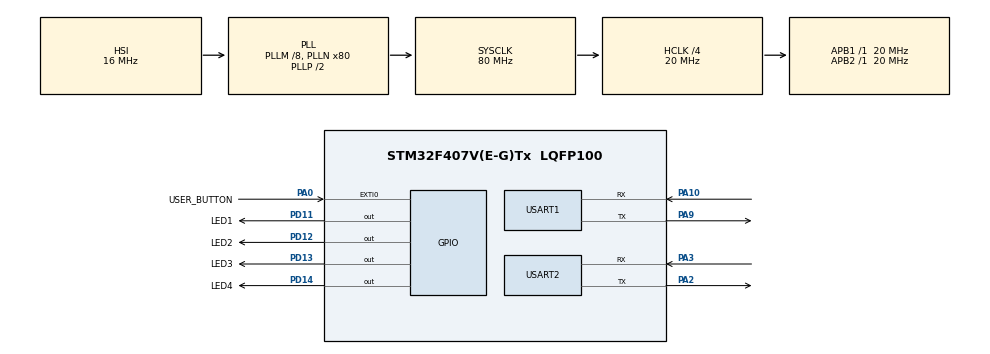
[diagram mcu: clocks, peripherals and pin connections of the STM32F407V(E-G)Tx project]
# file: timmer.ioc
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Mcu.Family=STM32F4
Mcu.Name=STM32F407V(E-G)Tx
Mcu.Package=LQFP100
NVIC.PriorityGroup=NVIC_PRIORITYGROUP_4
NVIC.TIM1_UP_TIM10_IRQn=true\:0\:0\:false\:false\:true\:true\:true\:true
PA0-WKUP.GPIO_Label=USER_BUTTON
PA0-WKUP.Signal=GPXTI0
PA10.Mode=Asynchronous
PA10.Signal=USART1_RX
PA2.Mode=Asynchronous
PA2.Signal=USART2_TX
PA3.Mode=Asynchronous
PA3.Signal=USART2_RX
PA9.Mode=Asynchronous
PA9.Signal=USART1_TX
PD11.GPIO_Label=LED1
PD11.Signal=GPIO_Output
PD12.GPIO_Label=LED2
PD12.Signal=GPIO_Output
PD13.GPIO_Label=LED3
PD13.Signal=GPIO_Output
PD14.GPIO_Label=LED4
PD14.Signal=GPIO_Output
ProjectManager.HeapSize=0x200
ProjectManager.StackSize=0x400
ProjectManager.TargetToolchain=Makefile
RCC.48MHZClocksFreq_Value=40000000
RCC.AHBCLKDivider=RCC_SYSCLK_DIV4
RCC.AHBFreq_Value=20000000
RCC.APB1Freq_Value=20000000
RCC.APB1TimFreq_Value=20000000
RCC.APB2Freq_Value=20000000
RCC.APB2TimFreq_Value=20000000
RCC.CortexFreq_Value=20000000
RCC.HCLKFreq_Value=20000000
RCC.HSE_VALUE=25000000
RCC.HSI_VALUE=16000000
RCC.LSE_VALUE=32768
RCC.PLLM=8
RCC.PLLN=80
RCC.SYSCLKFreq_VALUE=80000000
RCC.SYSCLKSource=RCC_SYSCLKSOURCE_PLLCLK
RCC.VCOOutputFreq_Value=160000000
TIM1.Period=1000
TIM1.Prescaler=20000
USART1.VirtualMode=VM_ASYNC
USART2.VirtualMode=VM_ASYNC
VP_TIM1_VS_ClockSourceINT.Mode=Internal
board=custom

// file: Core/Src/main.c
/* USER CODE BEGIN Header */
/**
  ******************************************************************************
  * @file           : main.c
  * @brief          : Main program body
  ******************************************************************************
  * @attention
  *
  * Copyright (c) 2022 STMicroelectronics.
  * All rights reserved.
  *
  * This software is licensed under terms that can be found in the LICENSE file
  * in the root directory of this software component.
  * If no LICENSE file comes with this software, it is provided AS-IS.
  *
  ******************************************************************************
  */
/* USER CODE END Header */
#include "main.h"

/* USER CODE BEGIN Includes */
#include <string.h>
#include <stdio.h>

/* USER CODE END Includes */

/* USER CODE BEGIN PTD */

// Utilizado para el contador
static uint32_t counter = 0;

/* USER CODE END PTD */

TIM_HandleTypeDef htim1;

UART_HandleTypeDef huart1;
UART_HandleTypeDef huart2;

void SystemClock_Config(void);
static void MX_GPIO_Init(void);
static void MX_TIM1_Init(void);
static void MX_USART1_UART_Init(void);
static void MX_USART2_UART_Init(void);

/* USER CODE BEGIN 0 */

char buffer[100]={0};

/* USER CODE END 0 */

int main(void)
{

  /* MCU Configuration--------------------------------------------------------*/

  /* Reset of all peripherals, Initializes the Flash interface and the Systick. */
  HAL_Init();

  /* Configure the system clock */
  SystemClock_Config();

  /* Initialize all configured peripherals */
  MX_GPIO_Init();
  MX_TIM1_Init();
  MX_USART1_UART_Init();
  MX_USART2_UART_Init();

  /* Infinite loop */
  /* USER CODE BEGIN WHILE */
  while (1)
  {

    HAL_GPIO_TogglePin(LED4_GPIO_Port,LED4_Pin);

    sprintf(buffer,"counter:%d \r\n",counter);
    HAL_UART_Transmit(&huart2,buffer,strlen(buffer),1000);
    HAL_Delay(1000);
    counter ++;
    /* USER CODE END WHILE */

  }
}

void SystemClock_Config(void)
{
  RCC_OscInitTypeDef RCC_OscInitStruct = {0};
  RCC_ClkInitTypeDef RCC_ClkInitStruct = {0};

  /** Configure the main internal regulator output voltage
  */
  __HAL_RCC_PWR_CLK_ENABLE();
  __HAL_PWR_VOLTAGESCALING_CONFIG(PWR_REGULATOR_VOLTAGE_SCALE1);

  /** Initializes the RCC Oscillators according to the specified parameters
  * in the RCC_OscInitTypeDef structure.
  */
  RCC_OscInitStruct.OscillatorType = RCC_OSCILLATORTYPE_HSI;
  RCC_OscInitStruct.HSIState = RCC_HSI_ON;
  RCC_OscInitStruct.HSICalibrationValue = RCC_HSICALIBRATION_DEFAULT;
  RCC_OscInitStruct.PLL.PLLState = RCC_PLL_ON;
  RCC_OscInitStruct.PLL.PLLSource = RCC_PLLSOURCE_HSI;
  RCC_OscInitStruct.PLL.PLLM = 8;
  RCC_OscInitStruct.PLL.PLLN = 80;
  RCC_OscInitStruct.PLL.PLLP = RCC_PLLP_DIV2;
  RCC_OscInitStruct.PLL.PLLQ = 4;
  if (HAL_RCC_OscConfig(&RCC_OscInitStruct) != HAL_OK)
  {
    Error_Handler();
  }

  /** Initializes the CPU, AHB and APB buses clocks
  */
  RCC_ClkInitStruct.ClockType = RCC_CLOCKTYPE_HCLK|RCC_CLOCKTYPE_SYSCLK
                              |RCC_CLOCKTYPE_PCLK1|RCC_CLOCKTYPE_PCLK2;
  RCC_ClkInitStruct.SYSCLKSource = RCC_SYSCLKSOURCE_PLLCLK;
  RCC_ClkInitStruct.AHBCLKDivider = RCC_SYSCLK_DIV4;
  RCC_ClkInitStruct.APB1CLKDivider = RCC_HCLK_DIV1;
  RCC_ClkInitStruct.APB2CLKDivider = RCC_HCLK_DIV1;

  if (HAL_RCC_ClockConfig(&RCC_ClkInitStruct, FLASH_LATENCY_0) != HAL_OK)
  {
    Error_Handler();
  }
}

static void MX_TIM1_Init(void)
{

  TIM_ClockConfigTypeDef sClockSourceConfig = {0};
  TIM_MasterConfigTypeDef sMasterConfig = {0};

  htim1.Instance = TIM1;
  htim1.Init.Prescaler = 20000;
  htim1.Init.CounterMode = TIM_COUNTERMODE_UP;
  htim1.Init.Period = 1000;
  htim1.Init.ClockDivision = TIM_CLOCKDIVISION_DIV1;
  htim1.Init.RepetitionCounter = 0;
  htim1.Init.AutoReloadPreload = TIM_AUTORELOAD_PRELOAD_DISABLE;
  if (HAL_TIM_Base_Init(&htim1) != HAL_OK)
  {
    Error_Handler();
  }
  sClockSourceConfig.ClockSource = TIM_CLOCKSOURCE_INTERNAL;
  if (HAL_TIM_ConfigClockSource(&htim1, &sClockSourceConfig) != HAL_OK)
  {
    Error_Handler();
  }
  sMasterConfig.MasterOutputTrigger = TIM_TRGO_RESET;
  sMasterConfig.MasterSlaveMode = TIM_MASTERSLAVEMODE_DISABLE;
  if (HAL_TIMEx_MasterConfigSynchronization(&htim1, &sMasterConfig) != HAL_OK)
  {
    Error_Handler();
  }

}

static void MX_USART1_UART_Init(void)
{

  huart1.Instance = USART1;
  huart1.Init.BaudRate = 115200;
  huart1.Init.WordLength = UART_WORDLENGTH_8B;
  huart1.Init.StopBits = UART_STOPBITS_1;
  huart1.Init.Parity = UART_PARITY_NONE;
  huart1.Init.Mode = UART_MODE_TX_RX;
  huart1.Init.HwFlowCtl = UART_HWCONTROL_NONE;
  huart1.Init.OverSampling = UART_OVERSAMPLING_16;
  if (HAL_UART_Init(&huart1) != HAL_OK)
  {
    Error_Handler();
  }

}

static void MX_USART2_UART_Init(void)
{

  huart2.Instance = USART2;
  huart2.Init.BaudRate = 115200;
  huart2.Init.WordLength = UART_WORDLENGTH_8B;
  huart2.Init.StopBits = UART_STOPBITS_1;
  huart2.Init.Parity = UART_PARITY_NONE;
  huart2.Init.Mode = UART_MODE_TX_RX;
  huart2.Init.HwFlowCtl = UART_HWCONTROL_NONE;
  huart2.Init.OverSampling = UART_OVERSAMPLING_16;
  if (HAL_UART_Init(&huart2) != HAL_OK)
  {
    Error_Handler();
  }

}

static void MX_GPIO_Init(void)
{
  GPIO_InitTypeDef GPIO_InitStruct = {0};

  /* GPIO Ports Clock Enable */
  __HAL_RCC_GPIOA_CLK_ENABLE();
  __HAL_RCC_GPIOD_CLK_ENABLE();

  /*Configure GPIO pin Output Level */
  HAL_GPIO_WritePin(GPIOD, LED1_Pin|LED2_Pin|LED3_Pin|LED4_Pin, GPIO_PIN_RESET);

  /*Configure GPIO pin : USER_BUTTON_Pin */
  GPIO_InitStruct.Pin = USER_BUTTON_Pin;
  GPIO_InitStruct.Mode = GPIO_MODE_IT_RISING;
  GPIO_InitStruct.Pull = GPIO_NOPULL;
  HAL_GPIO_Init(USER_BUTTON_GPIO_Port, &GPIO_InitStruct);

  /*Configure GPIO pins : LED1_Pin LED2_Pin LED3_Pin LED4_Pin */
  GPIO_InitStruct.Pin = LED1_Pin|LED2_Pin|LED3_Pin|LED4_Pin;
  GPIO_InitStruct.Mode = GPIO_MODE_OUTPUT_PP;
  GPIO_InitStruct.Pull = GPIO_NOPULL;
  GPIO_InitStruct.Speed = GPIO_SPEED_FREQ_LOW;
  HAL_GPIO_Init(GPIOD, &GPIO_InitStruct);

}

void Error_Handler(void)
{
  __disable_irq();
  while (1)
  {
  }
}
